# RA2A1 register map
Vendor: Renesas Electronics Corporation; Series: RA2; File version: 1.1
CPU: other r1p0, little endian, MPU, no FPU, VTOR, 2 interrupt priority bits
Registers are 8-bit, read-write, reset 0x0 unless marked. A register's access mark holds for its fields unless they carry their own. Offsets are from the block's base; [hi:lo] are bit positions; {n}, {i} and the like mark numbered series; 'fields as' and 'values as' point back to an identical list.

## DAC8 — 8-bit D/A converter
Base 0x4009E000
{0x0+i} DACS{i} (i=0..1) — D/A Conversion Value Setting Register {i}
  [7:0] DACS — DACS D/A conversion store data
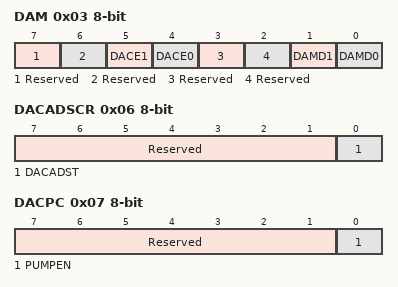
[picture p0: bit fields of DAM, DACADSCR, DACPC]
0x03 DAM — D/A Converter Mode Register
  [7] Reserved — This bit is read as 0. The write value should be 0.
  [6] Reserved — This bit is read as 0. The write value should be 0.
  [5] DACE1 — D/A operation enable 1
    0=D/A conversion disabled for channel 1; 1=D/A conversion enabled for channel 1
  [4] DACE0 — D/A operation enable 0
    0=D/A conversion disabled for channel 0; 1=D/A conversion enabled for channel 0
  [3] Reserved — This bit is read as 0. The write value should be 0.
  [2] Reserved — This bit is read as 0. The write value should be 0.
  [1] DAMD1 — D/A operation mode select 1
    0=Channel 1 for normal operation mode; 1=Channel 1 for real-time output mode(event link)
  [0] DAMD0 — D/A operation mode select 0
    0=Channel 0 for normal operation mode; 1=Channel 0 for real-time output mode(event link)
0x06 DACADSCR — D/A A/D Synchronous Start Control Register
  [7:1] Reserved — These bits are read as 0000000. The write value should be 0000000.
  [0] DACADST — D/A A/D Synchronous Conversion
    0=Do not synchronize DAC8 with ADC16 operation (disable interference reduction between D/A and A/D conversion); 1=Synchronize DAC8 with ADC16 operation (enable interference reduction between D/A and A/D conversion)
0x07 DACPC — D/A SW Charge Pump Control Register
  [7:1] Reserved — These bits are read as 0000000. The write value should be 0000000.
  [0] PUMPEN — Charge pump enable
    0=Charge pump disable; 1=Charge pump enable

## ELC — Event Link Controller
Base 0x40041000
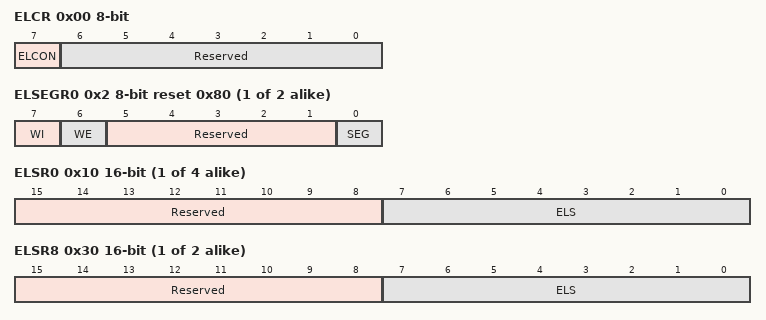
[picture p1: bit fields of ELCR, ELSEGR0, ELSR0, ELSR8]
0x00 ELCR — Event Link Controller Register
  [7] ELCON — All Event Link Enable
    0=ELC function is disabled; 1=ELC function is enabled
  [6:0] Reserved — These bits are read as 0000000. The write value should be 0000000.
{0x2+2i} ELSEGR{i} (i=0..1) reset 0x80 — Event Link Software Event Generation Register {i}
  [7] WI wo — ELSEGR Register Write Disable
    0=Write to ELSEGR register is enabled; 1=Write to ELSEGR register is disabled
  [6] WE — SEG Bit Write Enable
    0=Write to SEG bit is disabled; 1=Write to SEG bit is enabled
  [5:1] Reserved — These bits are read as 00000. The write value should be 00000.
  [0] SEG wo — Software Event Generation
    0=Normal operation; 1=Software event is generated
{0x10+4i} ELSR{i} (i=0..3) 16-bit — Event Link Setting Register {i}
  [15:8] Reserved — These bits are read as 00000000. The write value should be 00000000.
  [7:0] ELS — Event Link Select
    0=Event output to the corresponding peripheral module is disabled; other=others (Set the number for the event signal to be linked.)
{0x10+4i} ELSR{i} (i=8..9) 16-bit — Event Link Setting Register {i}
  fields as ELSR0
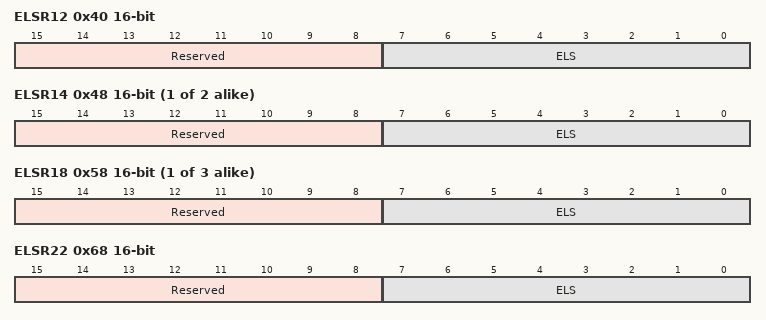
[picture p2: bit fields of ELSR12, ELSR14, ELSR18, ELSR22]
0x40 ELSR12 16-bit — Event Link Setting Register 12
  fields as ELSR0
{0x10+4i} ELSR{i} (i=14..15) 16-bit — Event Link Setting Register {i}
  fields as ELSR0
{0x10+4i} ELSR{i} (i=18..20) 16-bit — Event Link Setting Register {i}
  fields as ELSR0
0x68 ELSR22 16-bit — Event Link Setting Register 22
  fields as ELSR0

## IWDT — Independent Watchdog Timer
Base 0x40044400
0x00 IWDTRR reset 0xFF — IWDT Refresh Register
  [7:0] IWDTRR — The counter is refreshed by writing 0x00 and then writing 0xFF to this register.
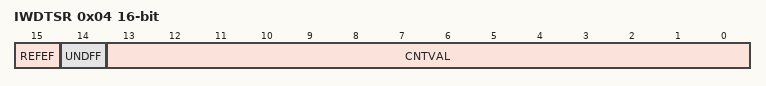
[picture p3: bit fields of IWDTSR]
0x04 IWDTSR 16-bit — IWDT Status Register
  [15] REFEF write-0-clears read-modifies — Refresh Error Flag
    0=Refresh error not occurred; 1=Refresh error occurred
  [14] UNDFF write-0-clears read-modifies — Underflow Flag
    0=Underflow not occurred; 1=Underflow occurred
  [13:0] CNTVAL ro — Counter ValueValue counted by the counter
